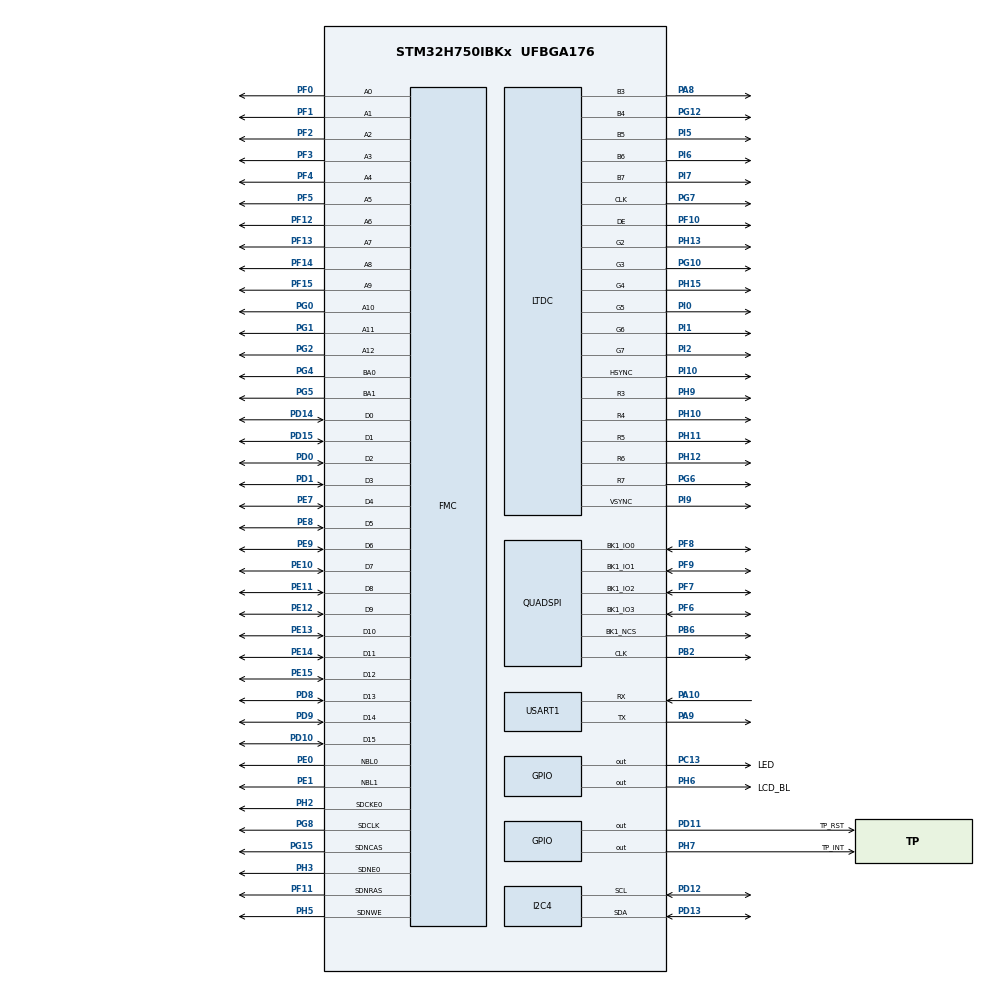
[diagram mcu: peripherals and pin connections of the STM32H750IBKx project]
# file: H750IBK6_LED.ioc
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CORTEX_M7.CPU_DCache=Enabled
CORTEX_M7.CPU_ICache=Enabled
DMA2D.ColorMode=DMA2D_OUTPUT_RGB565
FMC.CASLatency1=FMC_SDRAM_CAS_LATENCY_3
FMC.ColumnBitsNumber1=FMC_SDRAM_COLUMN_BITS_NUM_9
FMC.ExitSelfRefreshDelay1=7
FMC.LoadToActiveDelay1=2
FMC.RCDDelay1=2
FMC.RPDelay1=2
FMC.RPDelay2=2
FMC.ReadPipeDelay1=FMC_SDRAM_RPIPE_DELAY_1
FMC.ReadPipeDelay2=FMC_SDRAM_RPIPE_DELAY_1
FMC.RowCycleDelay1=7
FMC.RowCycleDelay2=7
FMC.SDClockPeriod1=FMC_SDRAM_CLOCK_PERIOD_2
FMC.SDClockPeriod2=FMC_SDRAM_CLOCK_PERIOD_2
FMC.SelfRefreshTime1=4
FMC.WriteRecoveryTime1=3
FREERTOS.Tasks01=defaultTask,24,128,StartDefaultTask,Default,NULL,Dynamic,NULL,NULL;myTask02,8,1024,StartTask02,Default,NULL,Dynamic,NULL,NULL
I2C4.Timing=0x307075B1
LTDC.ActiveH=600
LTDC.ActiveW=1024
LTDC.Alpha_L0=255
LTDC.FBStartAdress_L0=0xc0000000
LTDC.HBP=46
LTDC.HFP=40
LTDC.HSync=1
LTDC.ImageHeight_L0=600
LTDC.ImageWidth_L0=1024
LTDC.Layers=0
LTDC.PixelFormat_L0=LTDC_PIXEL_FORMAT_RGB565
LTDC.VBP=23
LTDC.VFP=10
LTDC.VSync=3
LTDC.WindowX1_L0=1024
LTDC.WindowY1_L0=600
Mcu.Family=STM32H7
Mcu.Name=STM32H750IBKx
Mcu.Package=UFBGA176
NVIC.DMA2D_IRQn=true\:5\:0\:false\:false\:true\:true\:true\:true\:true
NVIC.FMC_IRQn=true\:5\:0\:false\:false\:true\:true\:true\:true\:true
NVIC.HSEM1_IRQn=true\:5\:0\:false\:false\:true\:true\:true\:true\:true
NVIC.LTDC_IRQn=true\:5\:0\:false\:false\:true\:true\:true\:true\:true
NVIC.PriorityGroup=NVIC_PRIORITYGROUP_4
NVIC.QUADSPI_IRQn=true\:5\:0\:false\:false\:true\:true\:true\:true\:true
NVIC.TIM7_IRQn=true\:0\:0\:true\:false\:true\:false\:false\:true\:true
NVIC.TimeBase=TIM7_IRQn
NVIC.TimeBaseIP=TIM7
PA10.Mode=Asynchronous
PA10.Signal=USART1_RX
PA8.Mode=RGB565
PA8.Signal=LTDC_B3
PA9.Mode=Asynchronous
PA9.Signal=USART1_TX
PB2.Mode=Single Bank 1
PB2.Signal=QUADSPI_CLK
PB6.Mode=Single Bank 1
PB6.Signal=QUADSPI_BK1_NCS
PC13.GPIO_Label=LED
PC13.Signal=GPIO_Output
PC14-OSC32_IN\ (OSC32_IN).Mode=LSE-External-Oscillator
PC14-OSC32_IN\ (OSC32_IN).Signal=RCC_OSC32_IN
PC15-OSC32_OUT\ (OSC32_OUT).Mode=LSE-External-Oscillator
PC15-OSC32_OUT\ (OSC32_OUT).Signal=RCC_OSC32_OUT
PD0.Signal=FMC_D2_DA2
PD1.Signal=FMC_D3_DA3
PD10.Signal=FMC_D15_DA15
PD11.GPIO_Label=TP_RST
PD11.GPIO_ModeDefaultOutputPP=GPIO_MODE_OUTPUT_PP
PD11.GPIO_PuPd=GPIO_PULLUP
PD11.PinState=GPIO_PIN_SET
PD11.Signal=GPIO_Output
PD12.GPIO_Pu=GPIO_NOPULL
PD12.GPIO_Speed=GPIO_SPEED_FREQ_HIGH
PD12.Mode=I2C
PD12.Signal=I2C4_SCL
PD13.GPIO_Pu=GPIO_NOPULL
PD13.GPIO_Speed=GPIO_SPEED_FREQ_HIGH
PD13.Mode=I2C
PD13.Signal=I2C4_SDA
PD14.Signal=FMC_D0_DA0
PD15.Signal=FMC_D1_DA1
PD8.Signal=FMC_D13_DA13
PD9.Signal=FMC_D14_DA14
PE0.Signal=FMC_NBL0
PE1.Signal=FMC_NBL1
PE10.Signal=FMC_D7_DA7
PE11.Signal=FMC_D8_DA8
PE12.Signal=FMC_D9_DA9
PE13.Signal=FMC_D10_DA10
PE14.Signal=FMC_D11_DA11
PE15.Signal=FMC_D12_DA12
PE7.Signal=FMC_D4_DA4
PE8.Signal=FMC_D5_DA5
PE9.Signal=FMC_D6_DA6
PF0.Signal=FMC_A0
PF1.Signal=FMC_A1
PF10.Mode=RGB565
PF10.Signal=LTDC_DE
PF11.Signal=FMC_SDNRAS
PF12.Signal=FMC_A6
PF13.Signal=FMC_A7
PF14.Signal=FMC_A8
PF15.Signal=FMC_A9
PF2.Signal=FMC_A2
PF3.Signal=FMC_A3
PF4.Signal=FMC_A4
PF5.Signal=FMC_A5
PF6.Mode=Single Bank 1
PF6.Signal=QUADSPI_BK1_IO3
PF7.Mode=Single Bank 1
PF7.Signal=QUADSPI_BK1_IO2
PF8.Mode=Single Bank 1
PF8.Signal=QUADSPI_BK1_IO0
PF9.Mode=Single Bank 1
PF9.Signal=QUADSPI_BK1_IO1
PG0.Signal=FMC_A10
PG1.Signal=FMC_A11
PG10.Mode=RGB565
PG10.Signal=LTDC_G3
PG12.Mode=RGB565
PG12.Signal=LTDC_B4
PG15.Signal=FMC_SDNCAS
PG2.Signal=FMC_A12
PG4.Signal=FMC_A14_BA0
PG5.Signal=FMC_A15_BA1
PG6.Mode=RGB565
PG6.Signal=LTDC_R7
PG7.Mode=RGB565
PG7.Signal=LTDC_CLK
PG8.Signal=FMC_SDCLK
PH0-OSC_IN\ (PH0).Mode=HSE-External-Oscillator
PH0-OSC_IN\ (PH0).Signal=RCC_OSC_IN
PH1-OSC_OUT\ (PH1).Mode=HSE-External-Oscillator
PH1-OSC_OUT\ (PH1).Signal=RCC_OSC_OUT
PH10.Mode=RGB565
PH10.Signal=LTDC_R4
PH11.Mode=RGB565
PH11.Signal=LTDC_R5
PH12.Mode=RGB565
PH12.Signal=LTDC_R6
PH13.Mode=RGB565
PH13.Signal=LTDC_G2
PH15.Mode=RGB565
PH15.Signal=LTDC_G4
PH2.Mode=SdramChipSelect1_1
PH2.Signal=FMC_SDCKE0
PH3.Mode=SdramChipSelect1_1
PH3.Signal=FMC_SDNE0
PH5.Signal=FMC_SDNWE
PH6.GPIO_Label=LCD_BL
PH6.GPIO_ModeDefaultOutputPP=GPIO_MODE_OUTPUT_PP
PH6.GPIO_PuPd=GPIO_PULLUP
PH6.PinState=GPIO_PIN_SET
PH6.Signal=GPIO_Output
PH7.GPIO_Label=TP_INT
PH7.GPIO_PuPd=GPIO_PULLUP
PH7.PinState=GPIO_PIN_SET
PH7.Signal=GPIO_Output
PH9.Mode=RGB565
PH9.Signal=LTDC_R3
PI0.Mode=RGB565
PI0.Signal=LTDC_G5
PI1.Mode=RGB565
PI1.Signal=LTDC_G6
PI10.Mode=RGB565
PI10.Signal=LTDC_HSYNC
PI2.Mode=RGB565
PI2.Signal=LTDC_G7
PI5.Mode=RGB565
PI5.Signal=LTDC_B5
PI6.Mode=RGB565
PI6.Signal=LTDC_B6
PI7.Mode=RGB565
PI7.Signal=LTDC_B7
PI9.Mode=RGB565
PI9.Signal=LTDC_VSYNC
ProjectManager.HeapSize=0x800
ProjectManager.StackSize=0x800
ProjectManager.TargetToolchain=MDK-ARM V5.32
QUADSPI.ChipSelectHighTime=QSPI_CS_HIGH_TIME_4_CYCLE
QUADSPI.ClockPrescaler=1
QUADSPI.FifoThreshold=32
QUADSPI.FlashSize=24
QUADSPI.SampleShifting=QSPI_SAMPLE_SHIFTING_HALFCYCLE
RCC.ADCFreq_Value=50390625
RCC.APB1Freq_Value=120000000
RCC.APB2Freq_Value=120000000
RCC.APB3Freq_Value=120000000
RCC.APB4Freq_Value=120000000
RCC.CortexFreq_Value=480000000
RCC.D1PPRE=RCC_APB3_DIV2
RCC.D2PPRE1=RCC_APB1_DIV2
RCC.D2PPRE2=RCC_APB2_DIV2
RCC.D3PPRE=RCC_APB4_DIV2
RCC.DIVM1=5
RCC.DIVM3=25
RCC.DIVN1=192
RCC.DIVN3=150
RCC.DIVQ1=80
RCC.DIVR3=6
RCC.HCLKFreq_Value=240000000
RCC.HPRE=RCC_HCLK_DIV2
RCC.PLLSourceVirtual=RCC_PLLSOURCE_HSE
RCC.ProductRev=revV
RCC.SYSCLKFreq_VALUE=480000000
RCC.SYSCLKSource=RCC_SYSCLKSOURCE_PLLCLK
RCC.SupplySource=PWR_LDO_SUPPLY
RCC.USBFreq_Value=12000000
SH.FMC_A0.0=FMC_A0,13b-sda1
SH.FMC_A1.0=FMC_A1,13b-sda1
SH.FMC_A10.0=FMC_A10,13b-sda1
SH.FMC_A11.0=FMC_A11,13b-sda1
SH.FMC_A12.0=FMC_A12,13b-sda1
SH.FMC_A14_BA0.0=FMC_BA0,FourSdramBanks1
SH.FMC_A15_BA1.0=FMC_BA1,FourSdramBanks1
SH.FMC_A2.0=FMC_A2,13b-sda1
SH.FMC_A3.0=FMC_A3,13b-sda1
SH.FMC_A4.0=FMC_A4,13b-sda1
SH.FMC_A5.0=FMC_A5,13b-sda1
SH.FMC_A6.0=FMC_A6,13b-sda1
SH.FMC_A7.0=FMC_A7,13b-sda1
SH.FMC_A8.0=FMC_A8,13b-sda1
SH.FMC_A9.0=FMC_A9,13b-sda1
SH.FMC_D0_DA0.0=FMC_D0,sd-16b-d1
SH.FMC_D10_DA10.0=FMC_D10,sd-16b-d1
SH.FMC_D11_DA11.0=FMC_D11,sd-16b-d1
SH.FMC_D12_DA12.0=FMC_D12,sd-16b-d1
SH.FMC_D13_DA13.0=FMC_D13,sd-16b-d1
SH.FMC_D14_DA14.0=FMC_D14,sd-16b-d1
SH.FMC_D15_DA15.0=FMC_D15,sd-16b-d1
SH.FMC_D1_DA1.0=FMC_D1,sd-16b-d1
SH.FMC_D2_DA2.0=FMC_D2,sd-16b-d1
SH.FMC_D3_DA3.0=FMC_D3,sd-16b-d1
SH.FMC_D4_DA4.0=FMC_D4,sd-16b-d1
SH.FMC_D5_DA5.0=FMC_D5,sd-16b-d1
SH.FMC_D6_DA6.0=FMC_D6,sd-16b-d1
SH.FMC_D7_DA7.0=FMC_D7,sd-16b-d1
SH.FMC_D8_DA8.0=FMC_D8,sd-16b-d1
SH.FMC_D9_DA9.0=FMC_D9,sd-16b-d1
SH.FMC_NBL0.0=FMC_NBL0,Sd2ByteEnable1
SH.FMC_NBL1.0=FMC_NBL1,Sd2ByteEnable1
SH.FMC_SDCLK.0=FMC_SDCLK,13b-sda1
SH.FMC_SDNCAS.0=FMC_SDNCAS,13b-sda1
SH.FMC_SDNRAS.0=FMC_SDNRAS,13b-sda1
SH.FMC_SDNWE.0=FMC_SDNWE,13b-sda1
STMicroelectronics.X-CUBE-TOUCHGFX.4.22.0.ApplicationCcGraphicsJjApplication=TouchGFXOoGenerator
STMicroelectronics.X-CUBE-TOUCHGFX.4.22.0.tgfx_address1=0xc0000000
STMicroelectronics.X-CUBE-TOUCHGFX.4.22.0.tgfx_address2=0xc012c000
STMicroelectronics.X-CUBE-TOUCHGFX.4.22.0.tgfx_buffering_strategy=Double
STMicroelectronics.X-CUBE-TOUCHGFX.4.22.0.tgfx_display_interface=disp_ltdc
STMicroelectronics.X-CUBE-TOUCHGFX.4.22.0.tgfx_hardware_accelerator=dma_2d
STMicroelectronics.X-CUBE-TOUCHGFX.4.22.0.tgfx_location=By Address
STMicroelectronics.X-CUBE-TOUCHGFX.4.22.0.tgfx_oswrapper=CMSIS V2
STMicroelectronics.X-CUBE-TOUCHGFX.4.22.0.tgfx_vector_rendering=Enabled
STMicroelectronics.X-CUBE-TOUCHGFX.4.22.0.tgfx_vsync=vsync_ltdc
STMicroelectronics.X-CUBE-TOUCHGFX.4.22.0_IsPackSelfContextualization=true
USART1.VirtualMode-Asynchronous=VM_ASYNC
VP_CRC_VS_CRC.Mode=CRC_Activate
VP_DMA2D_VS_DMA2D.Mode=DMA2D_Activate
VP_FREERTOS_VS_CMSIS_V2.Mode=CMSIS_V2
VP_STMicroelectronics.X-CUBE-TOUCHGFX_VS_GraphicsJjApplication_4.22.0.Mode=GraphicsJjApplication
VP_SYS_VS_tim7.Mode=TIM7
board=custom

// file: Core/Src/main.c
/* USER CODE BEGIN Header */
/**
  ******************************************************************************
  * @file           : main.c
  * @brief          : Main program body
  ******************************************************************************
  * @attention
  *
  * Copyright (c) 2023 STMicroelectronics.
  * All rights reserved.
  *
  * This software is licensed under terms that can be found in the LICENSE file
  * in the root directory of this software component.
  * If no LICENSE file comes with this software, it is provided AS-IS.
  *
  ******************************************************************************
  */
/* USER CODE END Header */
#include "main.h"
#include "cmsis_os.h"
#include "crc.h"
#include "dma2d.h"
#include "i2c.h"
#include "ltdc.h"
#include "usart.h"
#include "gpio.h"
#include "fmc.h"
#include "app_touchgfx.h"

/* USER CODE BEGIN Includes */
#include "bsp_sdram.h"
#include <stdio.h>
#include "gt911.h"
/* USER CODE END Includes */

void SystemClock_Config(void);
void MX_FREERTOS_Init(void);
/* USER CODE BEGIN PFP */
void MPU_Config(void);
/* USER CODE END PFP */

/* USER CODE BEGIN 0 */
#ifdef __GNUC__
#define PUTCHAR_PROTOTYPE int __io_putchar(int ch)
#else
#define PUTCHAR_PROTOTYPE int fputc(int ch, FILE *f)
#endif
PUTCHAR_PROTOTYPE
{
    HAL_UART_Transmit(&huart1 , (uint8_t *)&ch, 1, 0xFFFF);
    return ch;
}

#define sdram_addr 0xc0000000
/* USER CODE END 0 */

int main(void)
{
  /* USER CODE BEGIN 1 */
	MPU_Config();
  /* USER CODE END 1 */
/* Enable the CPU Cache */

  /* Enable I-Cache---------------------------------------------------------*/
  SCB_EnableICache();

  /* Enable D-Cache---------------------------------------------------------*/
  SCB_EnableDCache();

  /* MCU Configuration--------------------------------------------------------*/

  /* Reset of all peripherals, Initializes the Flash interface and the Systick. */
  HAL_Init();

  /* Configure the system clock */
  SystemClock_Config();

  /* Initialize all configured peripherals */
  MX_GPIO_Init();
  MX_FMC_Init();
  MX_USART1_UART_Init();
  MX_DMA2D_Init();
  MX_LTDC_Init();
  MX_CRC_Init();
  MX_I2C4_Init();
  MX_TouchGFX_Init();
  /* Call PreOsInit function */
  MX_TouchGFX_PreOSInit();
  /* USER CODE BEGIN 2 */
	__HAL_RCC_FMC_CLK_ENABLE();
	__HAL_RCC_FMC_CLK_ENABLE();
	__FMC_NORSRAM_DISABLE(FMC_NORSRAM_DEVICE, FMC_NORSRAM_BANK1);
	__FMC_NORSRAM_DISABLE(FMC_NORSRAM_DEVICE, FMC_NORSRAM_BANK2);
	__FMC_NORSRAM_DISABLE(FMC_NORSRAM_DEVICE, FMC_NORSRAM_BANK3);
	__FMC_NORSRAM_DISABLE(FMC_NORSRAM_DEVICE, FMC_NORSRAM_BANK4);
//
	gt911_init();
	SDRAM_InitSequence();
  /* USER CODE END 2 */

  /* Init scheduler */
  osKernelInitialize();

  /* Call init function for freertos objects (in freertos.c) */
  MX_FREERTOS_Init();

  /* Start scheduler */
  osKernelStart();

  /* We should never get here as control is now taken by the scheduler */
  /* Infinite loop */
  /* USER CODE BEGIN WHILE */
  while (1)
  {
		HAL_Delay(500);
		HAL_GPIO_TogglePin(LED_GPIO_Port,LED_Pin);
    /* USER CODE END WHILE */

  }
}

void SystemClock_Config(void)
{
  RCC_OscInitTypeDef RCC_OscInitStruct = {0};
  RCC_ClkInitTypeDef RCC_ClkInitStruct = {0};

  /** Supply configuration update enable
  */
  HAL_PWREx_ConfigSupply(PWR_LDO_SUPPLY);

  /** Configure the main internal regulator output voltage
  */
  __HAL_PWR_VOLTAGESCALING_CONFIG(PWR_REGULATOR_VOLTAGE_SCALE1);

  while(!__HAL_PWR_GET_FLAG(PWR_FLAG_VOSRDY)) {}

  __HAL_RCC_SYSCFG_CLK_ENABLE();
  __HAL_PWR_VOLTAGESCALING_CONFIG(PWR_REGULATOR_VOLTAGE_SCALE0);

  while(!__HAL_PWR_GET_FLAG(PWR_FLAG_VOSRDY)) {}

  /** Initializes the RCC Oscillators according to the specified parameters
  * in the RCC_OscInitTypeDef structure.
  */
  RCC_OscInitStruct.OscillatorType = RCC_OSCILLATORTYPE_HSE;
  RCC_OscInitStruct.HSEState = RCC_HSE_ON;
  RCC_OscInitStruct.PLL.PLLState = RCC_PLL_ON;
  RCC_OscInitStruct.PLL.PLLSource = RCC_PLLSOURCE_HSE;
  RCC_OscInitStruct.PLL.PLLM = 5;
  RCC_OscInitStruct.PLL.PLLN = 192;
  RCC_OscInitStruct.PLL.PLLP = 2;
  RCC_OscInitStruct.PLL.PLLQ = 80;
  RCC_OscInitStruct.PLL.PLLR = 2;
  RCC_OscInitStruct.PLL.PLLRGE = RCC_PLL1VCIRANGE_2;
  RCC_OscInitStruct.PLL.PLLVCOSEL = RCC_PLL1VCOWIDE;
  RCC_OscInitStruct.PLL.PLLFRACN = 0;
  if (HAL_RCC_OscConfig(&RCC_OscInitStruct) != HAL_OK)
  {
    Error_Handler();
  }

  /** Initializes the CPU, AHB and APB buses clocks
  */
  RCC_ClkInitStruct.ClockType = RCC_CLOCKTYPE_HCLK|RCC_CLOCKTYPE_SYSCLK
                              |RCC_CLOCKTYPE_PCLK1|RCC_CLOCKTYPE_PCLK2
                              |RCC_CLOCKTYPE_D3PCLK1|RCC_CLOCKTYPE_D1PCLK1;
  RCC_ClkInitStruct.SYSCLKSource = RCC_SYSCLKSOURCE_PLLCLK;
  RCC_ClkInitStruct.SYSCLKDivider = RCC_SYSCLK_DIV1;
  RCC_ClkInitStruct.AHBCLKDivider = RCC_HCLK_DIV2;
  RCC_ClkInitStruct.APB3CLKDivider = RCC_APB3_DIV2;
  RCC_ClkInitStruct.APB1CLKDivider = RCC_APB1_DIV2;
  RCC_ClkInitStruct.APB2CLKDivider = RCC_APB2_DIV2;
  RCC_ClkInitStruct.APB4CLKDivider = RCC_APB4_DIV2;

  if (HAL_RCC_ClockConfig(&RCC_ClkInitStruct, FLASH_LATENCY_4) != HAL_OK)
  {
    Error_Handler();
  }
}

/* USER CODE BEGIN 4 */
void MPU_Config(void)
{
	MPU_Region_InitTypeDef MPU_InitStruct;

	HAL_MPU_Disable();		// �Ƚ�ֹMPU

	MPU_InitStruct.Enable           = MPU_REGION_ENABLE;
	MPU_InitStruct.BaseAddress      = SDRAM_BANK_ADDR;
	MPU_InitStruct.Size             = MPU_REGION_SIZE_32MB;
	MPU_InitStruct.AccessPermission = MPU_REGION_FULL_ACCESS;
	MPU_InitStruct.IsBufferable     = MPU_ACCESS_NOT_BUFFERABLE;
	MPU_InitStruct.IsCacheable      = MPU_ACCESS_CACHEABLE;
	MPU_InitStruct.IsShareable      = MPU_ACCESS_NOT_SHAREABLE;
	MPU_InitStruct.Number           = MPU_REGION_NUMBER2;
	MPU_InitStruct.TypeExtField     = MPU_TEX_LEVEL0;
	MPU_InitStruct.SubRegionDisable = 0x00;
	MPU_InitStruct.DisableExec      = MPU_INSTRUCTION_ACCESS_ENABLE;

	HAL_MPU_ConfigRegion(&MPU_InitStruct);

	HAL_MPU_Enable(MPU_PRIVILEGED_DEFAULT);	// ʹ��MPU

}
/* USER CODE END 4 */

void HAL_TIM_PeriodElapsedCallback(TIM_HandleTypeDef *htim)
{
  if (htim->Instance == TIM7) {
    HAL_IncTick();
  }
}

void Error_Handler(void)
{
  __disable_irq();
  while (1)
  {
  }
}
